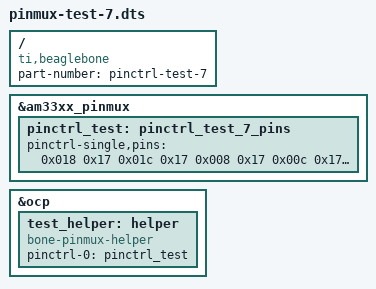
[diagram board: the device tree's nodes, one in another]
/dts-v1/;
/plugin/;
/{
	compatible = "ti,beaglebone", "ti,beaglebone-black";
	/* identification */
	part-number = "pinctrl-test-7";
	fragment@0 {
		target = <&am33xx_pinmux>;
		__overlay__ {
pinctrl_test: pinctrl_test_7_pins {
		      pinctrl-single,pins = <
			      /*   0x 0x17  P8_01 muxRegOffset, OUTPUT | MODE7 | PULLUP*/
			      /*   0x 0x17  P8_02 muxRegOffset, OUTPUT | MODE7 | PULLUP*/
			      0x018 0x17 /* P8_03 muxRegOffset, OUTPUT | MODE7 | PULLUP*/
			      0x01c 0x17 /* P8_04 muxRegOffset, OUTPUT | MODE7 | PULLUP*/
			      0x008 0x17 /* P8_05 muxRegOffset, OUTPUT | MODE7 | PULLUP*/
			      0x00c 0x17 /* P8_06 muxRegOffset, OUTPUT | MODE7 | PULLUP*/
			      0x090 0x17 /* P8_07 muxRegOffset, OUTPUT | MODE7 | PULLUP*/
			      0x094 0x17 /* P8_08 muxRegOffset, OUTPUT | MODE7 | PULLUP*/
			      0x09c 0x17 /* P8_09 muxRegOffset, OUTPUT | MODE7 | PULLUP*/
			      0x098 0x17 /* P8_10 muxRegOffset, OUTPUT | MODE7 | PULLUP*/
			      0x034 0x17 /* P8_11 muxRegOffset, OUTPUT | MODE7 | PULLUP*/
			      0x030 0x17 /* P8_12 muxRegOffset, OUTPUT | MODE7 | PULLUP*/
			      0x024 0x17 /* P8_13 muxRegOffset, OUTPUT | MODE7 | PULLUP*/
			      0x028 0x17 /* P8_14 muxRegOffset, OUTPUT | MODE7 | PULLUP*/
			      0x03c 0x17 /* P8_15 muxRegOffset, OUTPUT | MODE7 | PULLUP*/
			      0x038 0x17 /* P8_16 muxRegOffset, OUTPUT | MODE7 | PULLUP*/
			      0x02c 0x17 /* P8_17 muxRegOffset, OUTPUT | MODE7 | PULLUP*/
			      0x08c 0x17 /* P8_18 muxRegOffset, OUTPUT | MODE7 | PULLUP*/
			      0x020 0x17 /* P8_19 muxRegOffset, OUTPUT | MODE7 | PULLUP*/
			      0x084 0x17 /* P8_20 muxRegOffset, OUTPUT | MODE7 | PULLUP*/
			      0x080 0x17 /* P8_21 muxRegOffset, OUTPUT | MODE7 | PULLUP*/
			      0x014 0x17 /* P8_22 muxRegOffset, OUTPUT | MODE7 | PULLUP*/
			      0x010 0x17 /* P8_23 muxRegOffset, OUTPUT | MODE7 | PULLUP*/
			      0x004 0x17 /* P8_24 muxRegOffset, OUTPUT | MODE7 | PULLUP*/
			      0x000 0x17 /* P8_25 muxRegOffset, OUTPUT | MODE7 | PULLUP*/
			      0x07c 0x17 /* P8_26 muxRegOffset, OUTPUT | MODE7 | PULLUP*/
			      0x0e0 0x17 /* P8_27 muxRegOffset, OUTPUT | MODE7 | PULLUP*/
			      0x0e8 0x17 /* P8_28 muxRegOffset, OUTPUT | MODE7 | PULLUP*/
			      0x0e4 0x17 /* P8_29 muxRegOffset, OUTPUT | MODE7 | PULLUP*/
			      0x0ec 0x17 /* P8_30 muxRegOffset, OUTPUT | MODE7 | PULLUP*/
			      0x0d8 0x17 /* P8_31 muxRegOffset, OUTPUT | MODE7 | PULLUP*/
			      0x0dc 0x17 /* P8_32 muxRegOffset, OUTPUT | MODE7 | PULLUP*/
			      0x0d4 0x17 /* P8_33 muxRegOffset, OUTPUT | MODE7 | PULLUP*/
			      0x0cc 0x17 /* P8_34 muxRegOffset, OUTPUT | MODE7 | PULLUP*/
			      0x0d0 0x17 /* P8_35 muxRegOffset, OUTPUT | MODE7 | PULLUP*/
			      0x0c8 0x17 /* P8_36 muxRegOffset, OUTPUT | MODE7 | PULLUP*/
			      0x0c0 0x17 /* P8_37 muxRegOffset, OUTPUT | MODE7 | PULLUP*/
			      0x0c4 0x17 /* P8_38 muxRegOffset, OUTPUT | MODE7 | PULLUP*/
			      0x0b8 0x17 /* P8_39 muxRegOffset, OUTPUT | MODE7 | PULLUP*/
			      0x0bc 0x17 /* P8_40 muxRegOffset, OUTPUT | MODE7 | PULLUP*/
			      0x0b0 0x17 /* P8_41 muxRegOffset, OUTPUT | MODE7 | PULLUP*/
			      0x0b4 0x17 /* P8_42 muxRegOffset, OUTPUT | MODE7 | PULLUP*/
			      0x0a8 0x17 /* P8_43 muxRegOffset, OUTPUT | MODE7 | PULLUP*/
			      0x0ac 0x17 /* P8_44 muxRegOffset, OUTPUT | MODE7 | PULLUP*/
			      0x0a0 0x17 /* P8_45 muxRegOffset, OUTPUT | MODE7 | PULLUP*/
			      0x0a4 0x17 /* P8_46 muxRegOffset, OUTPUT | MODE7 | PULLUP*/
			      /* 0x 0x17    P9_01 muxRegOffset, OUTPUT | MODE7 | PULLUP*/
			      /* 0x 0x17    P9_02 muxRegOffset, OUTPUT | MODE7 | PULLUP*/
			      /* 0x 0x17    P9_03 muxRegOffset, OUTPUT | MODE7 | PULLUP*/
			      /* 0x 0x17    P9_04 muxRegOffset, OUTPUT | MODE7 | PULLUP*/
			      /* 0x 0x17    P9_05 muxRegOffset, OUTPUT | MODE7 | PULLUP*/
			      /* 0x 0x17    P9_06 muxRegOffset, OUTPUT | MODE7 | PULLUP*/
			      /* 0x 0x17    P9_07 muxRegOffset, OUTPUT | MODE7 | PULLUP*/
			      /* 0x 0x17    P9_08 muxRegOffset, OUTPUT | MODE7 | PULLUP*/
			      /* 0x 0x17    P9_09 muxRegOffset, OUTPUT | MODE7 | PULLUP*/
			      /* 0x 0x17    P9_10 muxRegOffset, OUTPUT | MODE7 | PULLUP*/
			      0x070 0x17 /* P9_11 muxRegOffset, OUTPUT | MODE7 | PULLUP*/
			      0x078 0x17 /* P9_12 muxRegOffset, OUTPUT | MODE7 | PULLUP*/
			      0x074 0x17 /* P9_13 muxRegOffset, OUTPUT | MODE7 | PULLUP*/
			      0x048 0x17 /* P9_14 muxRegOffset, OUTPUT | MODE7 | PULLUP*/
			      0x040 0x17 /* P9_15 muxRegOffset, OUTPUT | MODE7 | PULLUP*/
			      0x04c 0x17 /* P9_16 muxRegOffset, OUTPUT | MODE7 | PULLUP*/
			      0x15c 0x17 /* P9_17 muxRegOffset, OUTPUT | MODE7 | PULLUP*/
			      0x158 0x17 /* P9_18 muxRegOffset, OUTPUT | MODE7 | PULLUP*/
			      /*0x17c 0x17  P9_19 muxRegOffset, OUTPUT | MODE7 | PULLUP*/
			      0x178 0x17 /* P9_20 muxRegOffset, OUTPUT | MODE7 | PULLUP*/
			      0x154 0x17 /* P9_21 muxRegOffset, OUTPUT | MODE7 | PULLUP*/
			      0x150 0x17 /* P9_22 muxRegOffset, OUTPUT | MODE7 | PULLUP*/
			      0x044 0x17 /* P9_23 muxRegOffset, OUTPUT | MODE7 | PULLUP*/
			      0x184 0x17 /* P9_24 muxRegOffset, OUTPUT | MODE7 | PULLUP*/
			      0x1ac 0x17 /* P9_25 muxRegOffset, OUTPUT | MODE7 | PULLUP*/
			      0x180 0x17 /* P9_26 muxRegOffset, OUTPUT | MODE7 | PULLUP*/
			      0x1a4 0x17 /* P9_27 muxRegOffset, OUTPUT | MODE7 | PULLUP*/
			      0x19c 0x17 /* P9_28 muxRegOffset, OUTPUT | MODE7 | PULLUP*/
			      0x194 0x17 /* P9_29 muxRegOffset, OUTPUT | MODE7 | PULLUP*/
			      0x198 0x17 /* P9_30 muxRegOffset, OUTPUT | MODE7 | PULLUP*/
			      0x190 0x17 /* P9_31 muxRegOffset, OUTPUT | MODE7 | PULLUP*/
			      /*   0x 0x17  P9_32 muxRegOffset, OUTPUT | MODE7 | PULLUP*/
			      /*   0x 0x17  P9_33 muxRegOffset, OUTPUT | MODE7 | PULLUP*/
			      /*   0x 0x17  P9_34 muxRegOffset, OUTPUT | MODE7 | PULLUP*/
			      /*   0x 0x17  P9_35 muxRegOffset, OUTPUT | MODE7 | PULLUP*/
			      /*   0x 0x17  P9_36 muxRegOffset, OUTPUT | MODE7 | PULLUP*/
			      /*   0x 0x17  P9_37 muxRegOffset, OUTPUT | MODE7 | PULLUP*/
			      /*   0x 0x17  P9_38 muxRegOffset, OUTPUT | MODE7 | PULLUP*/
			      /*   0x 0x17  P9_39 muxRegOffset, OUTPUT | MODE7 | PULLUP*/
			      /*   0x 0x17  P9_40 muxRegOffset, OUTPUT | MODE7 | PULLUP*/
			      0x1b4 0x17 /* P9_41 muxRegOffset, OUTPUT | MODE7 | PULLUP*/
			      0x164 0x17 /* P9_42 muxRegOffset, OUTPUT | MODE7 | PULLUP*/
			      /*    0x 0x17 P9_43 muxRegOffset, OUTPUT | MODE7 | PULLUP*/
			      /*    0x 0x17 P9_44 muxRegOffset, OUTPUT | MODE7 | PULLUP*/
			      /*    0x 0x17 P9_45 muxRegOffset, OUTPUT | MODE7 | PULLUP*/
			      /*    0x 0x17 P9_46 muxRegOffset, OUTPUT | MODE7 | PULLUP*/
			      >;
	      };
		};
	};
	fragment@1 {
		target = <&ocp>;
		__overlay__ {
test_helper: helper {
		     compatible = "bone-pinmux-helper";
		     pinctrl-names = "default";
		     pinctrl-0 = <&pinctrl_test>;
		     status = "okay";
	     };
		};
	};
};

